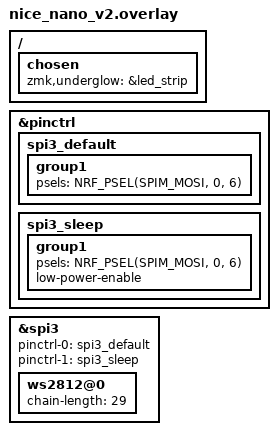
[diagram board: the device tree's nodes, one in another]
#include <dt-bindings/led/led.h>

/* (Optionnel) seulement si tu dois vraiment forcer la pin MOSI */
&pinctrl {
    spi3_default: spi3_default {
        group1 { psels = <NRF_PSEL(SPIM_MOSI, 0, 6)>; };
    };

    spi3_sleep: spi3_sleep {
        group1 {
            psels = <NRF_PSEL(SPIM_MOSI, 0, 6)>;
            low-power-enable;
        };
    };
};

/* On garde spi3 activé, mais on NE recrée PAS le node ws2812 */
&spi3 {
    status = "okay";
    pinctrl-0 = <&spi3_default>;
    pinctrl-1 = <&spi3_sleep>;
    pinctrl-names = "default", "sleep";

    ws2812@0 {
        /* On override juste la longueur */
        chain-length = <29>;
    };
};

/ {
    chosen {
        zmk,underglow = &led_strip;
    };
};
